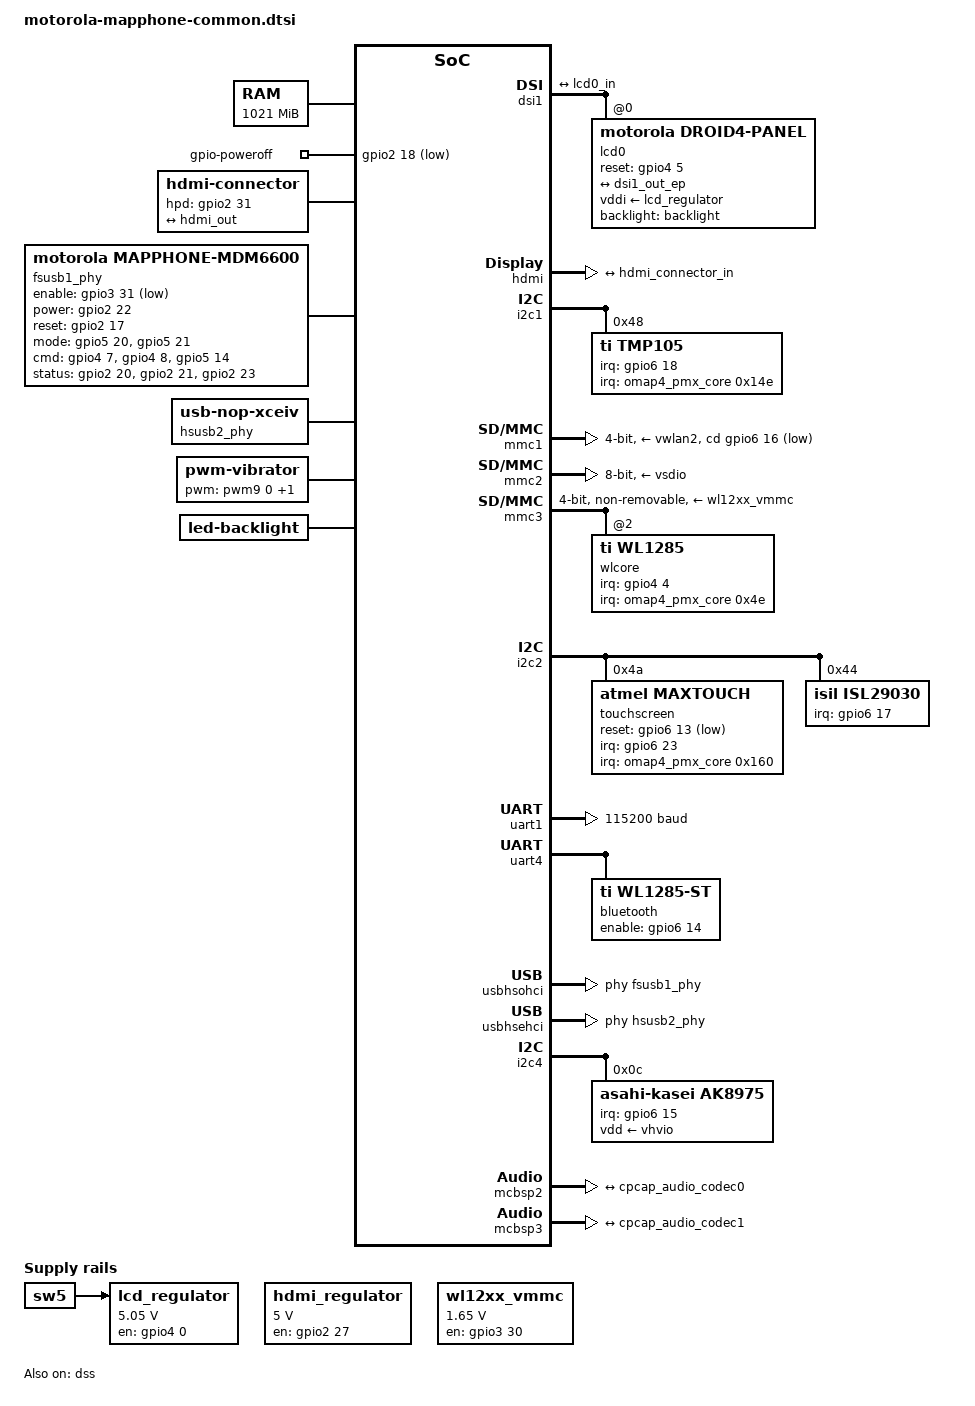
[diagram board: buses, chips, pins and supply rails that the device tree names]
/dts-v1/;
#include <dt-bindings/input/input.h>
#include "omap443x.dtsi"
#include "motorola-cpcap-mapphone.dtsi"
/ {
	chosen {
		stdout-path = &uart3;
	};
	aliases {
		display0 = &lcd0;
		display1 = &hdmi0;
	};
	memory {
		device_type = "memory";
		reg = <0x80000000 0x3fd00000>;	 
	};
	gpio-poweroff {
		compatible = "gpio-poweroff";
		pinctrl-0 = <&poweroff_gpio>;
		pinctrl-names = "default";
		gpios = <&gpio2 18 GPIO_ACTIVE_LOW>;	 
	};
	hdmi0: connector {
		compatible = "hdmi-connector";
		pinctrl-0 = <&hdmi_hpd_gpio>;
		pinctrl-names = "default";
		label = "hdmi";
		type = "d";
		hpd-gpios = <&gpio2 31 GPIO_ACTIVE_HIGH>;	 
		port {
			hdmi_connector_in: endpoint {
				remote-endpoint = <&hdmi_out>;
			};
		};
	};
	hdmi_regulator: regulator-hdmi {
		compatible = "regulator-fixed";
		regulator-name = "hdmi";
		regulator-min-microvolt = <5000000>;
		regulator-max-microvolt = <5000000>;
		gpio = <&gpio2 27 GPIO_ACTIVE_HIGH>;	 
		enable-active-high;
		regulator-always-on;
	};
	fsusb1_phy: usb-phy@1 {
		compatible = "motorola,mapphone-mdm6600";
		pinctrl-0 = <&usb_mdm6600_pins>;
		pinctrl-names = "default";
		enable-gpios = <&gpio3 31 GPIO_ACTIVE_LOW>;      
		power-gpios = <&gpio2 22 GPIO_ACTIVE_HIGH>;	 
		reset-gpios = <&gpio2 17 GPIO_ACTIVE_HIGH>;	 
		motorola,mode-gpios = <&gpio5 20 GPIO_ACTIVE_HIGH>,
				      <&gpio5 21 GPIO_ACTIVE_HIGH>;
		motorola,cmd-gpios = <&gpio4 7 GPIO_ACTIVE_HIGH>,
				     <&gpio4 8 GPIO_ACTIVE_HIGH>,
				     <&gpio5 14 GPIO_ACTIVE_HIGH>;
		motorola,status-gpios = <&gpio2 20 GPIO_ACTIVE_HIGH>,
					<&gpio2 21 GPIO_ACTIVE_HIGH>,
					<&gpio2 23 GPIO_ACTIVE_HIGH>;
		#phy-cells = <0>;
	};
	hsusb2_phy: usb-phy@2 {
		compatible = "usb-nop-xceiv";
		#phy-cells = <0>;
	};
	lcd_regulator: regulator-lcd {
		compatible = "regulator-fixed";
		regulator-name = "lcd";
		regulator-min-microvolt = <5050000>;
		regulator-max-microvolt = <5050000>;
		gpio = <&gpio4 0 GPIO_ACTIVE_HIGH>;	 
		enable-active-high;
		vin-supply = <&sw5>;
	};
	wl12xx_vmmc: regulator-wl12xx {
		compatible = "regulator-fixed";
		regulator-name = "vwl1271";
		regulator-min-microvolt = <1650000>;
		regulator-max-microvolt = <1650000>;
		gpio = <&gpio3 30 GPIO_ACTIVE_HIGH>;	 
		startup-delay-us = <70000>;
		enable-active-high;
	};
	soundcard {
		compatible = "audio-graph-card";
		label = "Mapphone Audio";
		widgets =
			"Speaker", "Earpiece",
			"Speaker", "Loudspeaker",
			"Headphone", "Headphone Jack",
			"Microphone", "Internal Mic";
		routing =
			"Earpiece", "EP",
			"Loudspeaker", "SPKR",
			"Headphone Jack", "HSL",
			"Headphone Jack", "HSR",
			"MICR", "Internal Mic";
		dais = <&mcbsp2_port>, <&mcbsp3_port>;
	};
	pwm8: pwm-8 {
		pinctrl-names = "default";
		pinctrl-0 = <&vibrator_direction_pin>;
		compatible = "ti,omap-dmtimer-pwm";
		#pwm-cells = <3>;
		ti,timers = <&timer8>;
		ti,clock-source = <0x01>;
	};
	pwm9: pwm-9 {
		pinctrl-names = "default";
		pinctrl-0 = <&vibrator_enable_pin>;
		compatible = "ti,omap-dmtimer-pwm";
		#pwm-cells = <3>;
		ti,timers = <&timer9>;
		ti,clock-source = <0x01>;
	};
	vibrator {
		compatible = "pwm-vibrator";
		pwms = <&pwm9 0 10000000 0>, <&pwm8 0 10000000 0>;
		pwm-names = "enable", "direction";
		direction-duty-cycle-ns = <10000000>;
	};
	backlight: backlight {
		compatible = "led-backlight";
		leds = <&backlight_led>;
		brightness-levels = <31 63 95 127 159 191 223 255>;
		default-brightness-level = <6>;
	};
};
&cpu_thermal {
	polling-delay = <10000>;  
};
&cpu_alert0 {
        temperature = <80000>;  
};
&cpu0 {
        operating-points = <
	        300000  1025000
	        600000  1200000
	        800000  1313000
	        1008000 1375000
		1200000 1375000
        >;
};
&dss {
	status = "okay";
};
&dsi1 {
	status = "okay";
	vdd-supply = <&vcsi>;
	port {
		dsi1_out_ep: endpoint {
			remote-endpoint = <&lcd0_in>;
			lanes = <0 1 2 3 4 5>;
		};
	};
	lcd0: panel@0 {
		compatible = "motorola,droid4-panel", "panel-dsi-cm";
		reg = <0>;
		label = "lcd0";
		vddi-supply = <&lcd_regulator>;
		reset-gpios = <&gpio4 5 GPIO_ACTIVE_HIGH>;	 
		backlight = <&backlight>;
		width-mm = <50>;
		height-mm = <89>;
		rotation = <90>;
		panel-timing {
			clock-frequency = <0>;		 
			hback-porch = <2>;
			hactive = <540>;
			hfront-porch = <0>;
			hsync-len = <2>;
			vback-porch = <1>;
			vactive = <960>;
			vfront-porch = <0>;
			vsync-len = <1>;
			hsync-active = <0>;
			vsync-active = <0>;
			de-active = <1>;
			pixelclk-active = <1>;
		};
		port {
			lcd0_in: endpoint {
				remote-endpoint = <&dsi1_out_ep>;
			};
		};
	};
};
&hdmi {
	status = "okay";
	pinctrl-0 = <&dss_hdmi_pins>;
	pinctrl-names = "default";
	vdda-supply = <&vdac>;
	port {
		hdmi_out: endpoint {
			remote-endpoint = <&hdmi_connector_in>;
			lanes = <1 0 3 2 5 4 7 6>;
		};
	};
};
&hdqw1w {
	pinctrl-0 = <&hdq_pins>;
	pinctrl-names = "default";
	ti,mode = "1w";
};
&i2c1 {
	tmp105@48 {
		compatible = "ti,tmp105";
		reg = <0x48>;
		pinctrl-0 = <&tmp105_irq>;
		pinctrl-names = "default";
		interrupts-extended = <&gpio6 18 IRQ_TYPE_EDGE_FALLING
				       &omap4_pmx_core 0x14e>;
		interrupt-names = "irq", "wakeup";
		wakeup-source;
	};
};
&mmc1 {
	vmmc-supply = <&vwlan2>;
	bus-width = <4>;
	cd-gpios = <&gpio6 16 GPIO_ACTIVE_LOW>;	 
};
&mmc2 {
	vmmc-supply = <&vsdio>;
	bus-width = <8>;
	ti,non-removable;
};
&mmc3 {
	pinctrl-names = "default";
	pinctrl-0 = <&mmc3_pins>;
	vmmc-supply = <&wl12xx_vmmc>;
	interrupts-extended = <&wakeupgen GIC_SPI 94 IRQ_TYPE_LEVEL_HIGH
			       &omap4_pmx_core 0xde>;
	interrupt-names = "irq", "wakeup";
	non-removable;
	bus-width = <4>;
	cap-power-off-card;
	keep-power-in-suspend;
	#address-cells = <1>;
	#size-cells = <0>;
	wlcore: wlcore@2 {
		compatible = "ti,wl1285";
		reg = <2>;
		interrupts-extended = <&gpio4 4 IRQ_TYPE_LEVEL_HIGH>,
				      <&omap4_pmx_core 0x4e>;
		interrupt-names = "irq", "wakeup";
		ref-clock-frequency = <26000000>;
		tcxo-clock-frequency = <26000000>;
	};
};
&i2c2 {
	touchscreen@4a {
		compatible = "atmel,maxtouch";
		reg = <0x4a>;
		pinctrl-names = "default";
		pinctrl-0 = <&touchscreen_pins>;
		reset-gpios = <&gpio6 13 GPIO_ACTIVE_LOW>;  
		interrupts-extended = <&gpio6 23 IRQ_TYPE_LEVEL_LOW>,
				      <&omap4_pmx_core 0x160>;
		interrupt-names = "irq", "wakeup";
		wakeup-source;
	};
	isl29030@44 {
		compatible = "isil,isl29030";
		reg = <0x44>;
		pinctrl-names = "default";
		pinctrl-0 = <&als_proximity_pins>;
		interrupt-parent = <&gpio6>;
		interrupts = <17 IRQ_TYPE_LEVEL_LOW>;  
	};
};
&omap4_pmx_core {
	hdmi_hpd_gpio: hdmi-hpd-pins {
		pinctrl-single,pins = <
		OMAP4_IOPAD(0x098, PIN_INPUT | MUX_MODE3)
		>;
	};
	hdq_pins: hdq-pins {
		pinctrl-single,pins = <
		OMAP4_IOPAD(0x120, PIN_INPUT | MUX_MODE0)
		>;
	};
	dss_hdmi_pins: dss-hdmi-pins {
		pinctrl-single,pins = <
		OMAP4_IOPAD(0x09a, PIN_INPUT | MUX_MODE0)
		OMAP4_IOPAD(0x09c, PIN_INPUT | MUX_MODE0)
		OMAP4_IOPAD(0x09e, PIN_INPUT | MUX_MODE0)
		>;
	};
	mmc3_pins: mmc3-pins {
		pinctrl-single,pins = <
		OMAP4_IOPAD(0x08e, PIN_INPUT | MUX_MODE3)
		OMAP4_IOPAD(0x102, PIN_INPUT_PULLUP | MUX_MODE1)
		OMAP4_IOPAD(0x104, PIN_INPUT_PULLUP | MUX_MODE1)
		OMAP4_IOPAD(0x118, PIN_INPUT | MUX_MODE1)
		OMAP4_IOPAD(0x11a, PIN_INPUT_PULLUP | MUX_MODE1)
		OMAP4_IOPAD(0x11c, PIN_INPUT_PULLUP | MUX_MODE1)
		OMAP4_IOPAD(0x11e, PIN_INPUT_PULLUP | MUX_MODE1)
		>;
	};
	poweroff_gpio: poweroff-pins {
		pinctrl-single,pins = <
		OMAP4_IOPAD(0x074, PIN_OUTPUT_PULLUP | MUX_MODE3)
		>;
	};
	tmp105_irq: tmp105-irq-pins {
		pinctrl-single,pins = <
		OMAP4_IOPAD(0x18e, PIN_INPUT_PULLUP | MUX_MODE3)
		>;
	};
	usb_gpio_mux_sel1: usb-gpio-mux-sel1-pins {
		pinctrl-single,pins = <
		OMAP4_IOPAD(0x088, PIN_OUTPUT | MUX_MODE3)
		>;
	};
	touchscreen_pins: touchscreen-pins {
		pinctrl-single,pins = <
		OMAP4_IOPAD(0x180, PIN_OUTPUT | MUX_MODE3)
		OMAP4_IOPAD(0x1a0, PIN_INPUT_PULLUP | MUX_MODE3)
		>;
	};
	als_proximity_pins: als-proximity-pins {
		pinctrl-single,pins = <
		OMAP4_IOPAD(0x18c, PIN_INPUT_PULLUP | MUX_MODE3)
		>;
	};
	usb_mdm6600_pins: usb-mdm6600-pins {
		pinctrl-single,pins = <
		OMAP4_IOPAD(0x0d8, PIN_INPUT | MUX_MODE3)
		OMAP4_IOPAD(0x07c, PIN_OUTPUT | MUX_MODE3)
		OMAP4_IOPAD(0x072, PIN_OUTPUT | MUX_MODE3)
		OMAP4_IOPAD(0x14e, PIN_OUTPUT | MUX_MODE3)
		OMAP4_IOPAD(0x150, PIN_OFF_OUTPUT_LOW | PIN_INPUT | MUX_MODE3)
		OMAP4_IOPAD(0x07e, PIN_INPUT | MUX_MODE3)
		OMAP4_IOPAD(0x07a, PIN_INPUT | MUX_MODE3)
		OMAP4_IOPAD(0x078, PIN_INPUT | MUX_MODE3)
		OMAP4_IOPAD(0x094, PIN_OUTPUT | MUX_MODE3)
		OMAP4_IOPAD(0x096, PIN_OUTPUT | MUX_MODE3)
		OMAP4_IOPAD(0x142, PIN_OUTPUT | MUX_MODE3)
		>;
	};
	usb_ulpi_pins: usb-ulpi-pins {
		pinctrl-single,pins = <
		OMAP4_IOPAD(0x196, MUX_MODE7)
		OMAP4_IOPAD(0x198, MUX_MODE7)
		OMAP4_IOPAD(0x1b2, PIN_INPUT_PULLUP | MUX_MODE0)
		OMAP4_IOPAD(0x1b4, PIN_INPUT_PULLUP | MUX_MODE0)
		OMAP4_IOPAD(0x1b6, PIN_INPUT_PULLUP | MUX_MODE0)
		OMAP4_IOPAD(0x1b8, PIN_INPUT_PULLUP | MUX_MODE0)
		OMAP4_IOPAD(0x1ba, PIN_INPUT_PULLUP | MUX_MODE0)
		OMAP4_IOPAD(0x1bc, PIN_INPUT_PULLUP | MUX_MODE0)
		OMAP4_IOPAD(0x1be, PIN_INPUT_PULLUP | MUX_MODE0)
		OMAP4_IOPAD(0x1c0, PIN_INPUT_PULLUP | MUX_MODE0)
		OMAP4_IOPAD(0x1c2, PIN_INPUT_PULLUP | MUX_MODE0)
		OMAP4_IOPAD(0x1c4, PIN_INPUT_PULLUP | MUX_MODE0)
		OMAP4_IOPAD(0x1c6, PIN_INPUT_PULLUP | MUX_MODE0)
		OMAP4_IOPAD(0x1c8, PIN_INPUT_PULLUP | MUX_MODE0)
		>;
	};
	usb_utmi_pins: usb-utmi-pins {
		pinctrl-single,pins = <
		OMAP4_IOPAD(0x196, PIN_INPUT | MUX_MODE0)
		OMAP4_IOPAD(0x198, PIN_INPUT | MUX_MODE0)
		OMAP4_IOPAD(0x1b2, PIN_INPUT_PULLUP | MUX_MODE7)
		OMAP4_IOPAD(0x1b4, PIN_INPUT_PULLUP | MUX_MODE7)
		OMAP4_IOPAD(0x1b6, PIN_INPUT_PULLUP | MUX_MODE7)
		OMAP4_IOPAD(0x1b8, PIN_INPUT_PULLUP | MUX_MODE7)
		OMAP4_IOPAD(0x1ba, PIN_INPUT_PULLUP | MUX_MODE7)
		OMAP4_IOPAD(0x1bc, PIN_INPUT_PULLUP | MUX_MODE7)
		OMAP4_IOPAD(0x1be, PIN_INPUT_PULLUP | MUX_MODE7)
		OMAP4_IOPAD(0x1c0, PIN_INPUT_PULLUP | MUX_MODE7)
		OMAP4_IOPAD(0x1c2, PIN_INPUT_PULLUP | MUX_MODE7)
		OMAP4_IOPAD(0x1c4, PIN_INPUT_PULLUP | MUX_MODE7)
		OMAP4_IOPAD(0x1c6, PIN_INPUT_PULLUP | MUX_MODE7)
		OMAP4_IOPAD(0x1c8, PIN_INPUT_PULLUP | MUX_MODE7)
		>;
	};
	uart1_pins: uart1-pins {
		pinctrl-single,pins = <
		OMAP4_IOPAD(0x13c, PIN_INPUT_PULLUP | MUX_MODE1)
		OMAP4_IOPAD(0x13e, MUX_MODE1)
		OMAP4_IOPAD(0x140, PIN_OUTPUT | MUX_MODE1)
		OMAP4_IOPAD(0x1ca, PIN_INPUT_PULLUP | MUX_MODE2)
		>;
	};
	uart3_pins: uart3-pins {
		pinctrl-single,pins = <
		OMAP4_IOPAD(0x196, MUX_MODE7)
		OMAP4_IOPAD(0x198, MUX_MODE7)
		OMAP4_IOPAD(0x1b2, PIN_INPUT_PULLUP | MUX_MODE7)
		OMAP4_IOPAD(0x1b4, PIN_INPUT_PULLUP | MUX_MODE7)
		OMAP4_IOPAD(0x1b6, PIN_INPUT_PULLUP | MUX_MODE7)
		OMAP4_IOPAD(0x1b8, PIN_INPUT_PULLUP | MUX_MODE7)
		OMAP4_IOPAD(0x1ba, MUX_MODE2)
		OMAP4_IOPAD(0x1bc, PIN_INPUT | MUX_MODE2)
		OMAP4_IOPAD(0x1be, PIN_INPUT_PULLUP | MUX_MODE7)
		OMAP4_IOPAD(0x1c0, PIN_INPUT_PULLUP | MUX_MODE7)
		OMAP4_IOPAD(0x1c2, PIN_INPUT_PULLUP | MUX_MODE7)
		OMAP4_IOPAD(0x1c4, PIN_INPUT_PULLUP | MUX_MODE7)
		OMAP4_IOPAD(0x1c6, PIN_INPUT_PULLUP | MUX_MODE7)
		OMAP4_IOPAD(0x1c8, PIN_INPUT_PULLUP | MUX_MODE7)
		>;
	};
	uart4_pins: uart4-pins {
		pinctrl-single,pins = <
		OMAP4_IOPAD(0x15c, PIN_INPUT | MUX_MODE0)		 
		OMAP4_IOPAD(0x15e, PIN_OUTPUT | MUX_MODE0)		 
		OMAP4_IOPAD(0x110, PIN_INPUT_PULLUP | MUX_MODE5)	 
		OMAP4_IOPAD(0x112, PIN_OUTPUT_PULLUP | MUX_MODE5)	 
		>;
	};
	mcbsp2_pins: mcbsp2-pins {
		pinctrl-single,pins = <
		OMAP4_IOPAD(0x0f6, PIN_INPUT | MUX_MODE0)	 
		OMAP4_IOPAD(0x0f8, PIN_INPUT | MUX_MODE0)	 
		OMAP4_IOPAD(0x0fa, PIN_OUTPUT | MUX_MODE0)	 
		OMAP4_IOPAD(0x0fc, PIN_INPUT | MUX_MODE0)	 
		>;
	};
	mcbsp3_pins: mcbsp3-pins {
		pinctrl-single,pins = <
		OMAP4_IOPAD(0x106, PIN_INPUT | MUX_MODE1)	 
		OMAP4_IOPAD(0x108, PIN_OUTPUT | MUX_MODE1)	 
		OMAP4_IOPAD(0x10a, PIN_INPUT | MUX_MODE1)	 
		OMAP4_IOPAD(0x10c, PIN_INPUT | MUX_MODE1)	 
		>;
	};
	vibrator_direction_pin: vibrator-direction-pins {
		pinctrl-single,pins = <
		OMAP4_IOPAD(0x1ce, PIN_OUTPUT | MUX_MODE1)	 
		>;
	};
	vibrator_enable_pin: vibrator-enable-pins {
		pinctrl-single,pins = <
		OMAP4_IOPAD(0X1d0, PIN_OUTPUT | MUX_MODE1)	 
		>;
	};
};
&omap4_pmx_wkup {
	usb_gpio_mux_sel2: usb-gpio-mux-sel2-pins {
		pinctrl-single,pins = <
		OMAP4_IOPAD(0x040, PIN_OUTPUT_PULLDOWN | MUX_MODE3)
		>;
	};
};
&rng_target {
	status = "disabled";
};
&timer8 {
	assigned-clocks = <&abe_clkctrl OMAP4_TIMER8_CLKCTRL 24>;
	assigned-clock-parents = <&sys_32k_ck>;
};
&timer9 {
	assigned-clocks = <&l4_per_clkctrl OMAP4_TIMER9_CLKCTRL 24>;
	assigned-clock-parents = <&sys_32k_ck>;
};
&uart1 {
	pinctrl-names = "default";
	pinctrl-0 = <&uart1_pins>;
	interrupts-extended = <&wakeupgen GIC_SPI 72 IRQ_TYPE_LEVEL_HIGH
			       &omap4_pmx_core 0x110>;
	uart-has-rtscts;
	current-speed = <115200>;
};
&uart3 {
	interrupts-extended = <&wakeupgen GIC_SPI 74 IRQ_TYPE_LEVEL_HIGH
			       &omap4_pmx_core 0x17c>;
	overrun-throttle-ms = <500>;
};
&uart4 {
	pinctrl-names = "default";
	pinctrl-0 = <&uart4_pins>;
	bluetooth {
		compatible = "ti,wl1285-st";
		enable-gpios = <&gpio6 14 GPIO_ACTIVE_HIGH>;  
		max-speed = <3686400>;
	};
};
&usbhsohci {
	phys = <&fsusb1_phy>;
	phy-names = "usb";
};
&usbhsehci {
	phys = <&hsusb2_phy>;
};
&usbhshost {
	port1-mode = "ohci-phy-4pin-dpdm";
	port2-mode = "ehci-tll";
};
&usb_otg_hs {
	interface-type = <1>;
	mode = <3>;
	power = <150>;
};
&i2c4 {
	ak8975: magnetometer@c {
		compatible = "asahi-kasei,ak8975";
		reg = <0x0c>;
		vdd-supply = <&vhvio>;
		interrupt-parent = <&gpio6>;
		interrupts = <15 IRQ_TYPE_EDGE_RISING>;  
		rotation-matrix = "-1", "0", "0",
				  "0", "1", "0",
				  "0", "0", "-1";
	};
};
&mcbsp2 {
	#sound-dai-cells = <0>;
	pinctrl-names = "default";
	pinctrl-0 = <&mcbsp2_pins>;
	status = "okay";
	mcbsp2_port: port {
		cpu_dai2: endpoint {
			dai-format = "i2s";
			remote-endpoint = <&cpcap_audio_codec0>;
			frame-master = <&cpcap_audio_codec0>;
			bitclock-master = <&cpcap_audio_codec0>;
		};
	};
};
&mcbsp3 {
	#sound-dai-cells = <0>;
	pinctrl-names = "default";
	pinctrl-0 = <&mcbsp3_pins>;
	status = "okay";
	mcbsp3_port: port {
		cpu_dai3: endpoint {
			dai-format = "dsp_a";
			frame-master = <&cpcap_audio_codec1>;
			bitclock-master = <&cpcap_audio_codec1>;
			remote-endpoint = <&cpcap_audio_codec1>;
		};
	};
};
&cpcap_audio_codec0 {
	remote-endpoint = <&cpu_dai2>;
};
&cpcap_audio_codec1 {
	remote-endpoint = <&cpu_dai3>;
};
